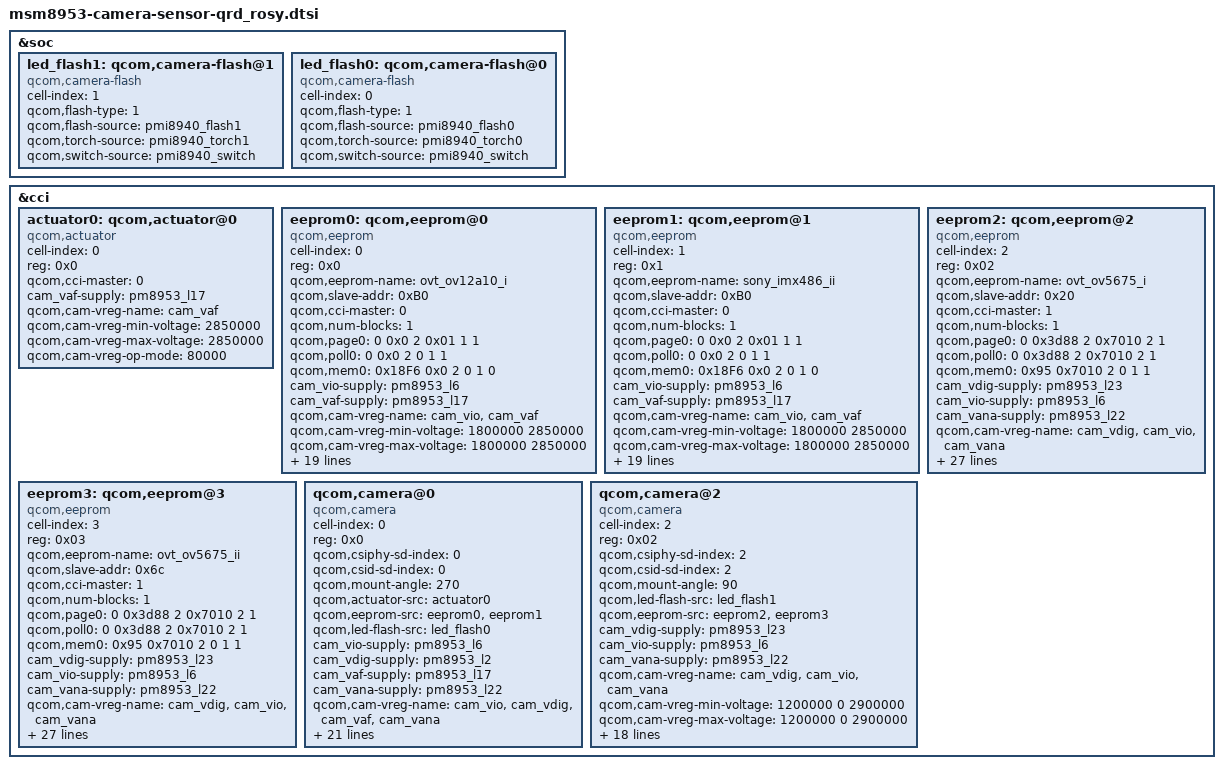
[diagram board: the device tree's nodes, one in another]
/*
 * Copyright (c) 2015-2016, The Linux Foundation. All rights reserved.
 *
 * This program is free software; you can redistribute it and/or modify
 * it under the terms of the GNU General Public License version 2 and
 * only version 2 as published by the Free Software Foundation.
 *
 * This program is distributed in the hope that it will be useful,
 * but WITHOUT ANY WARRANTY; without even the implied warranty of
 * MERCHANTABILITY or FITNESS FOR A PARTICULAR PURPOSE.  See the
 * GNU General Public License for more details.
 */

&soc {
	led_flash1: qcom,camera-flash@1 {
		cell-index = <1>;
		compatible = "qcom,camera-flash";
		qcom,flash-type = <1>;
		qcom,flash-source = <&pmi8940_flash1>;
		qcom,torch-source = <&pmi8940_torch1>;
		qcom,switch-source = <&pmi8940_switch>;
	};

	led_flash0: qcom,camera-flash@0 {
		cell-index = <0>;
		compatible = "qcom,camera-flash";
		qcom,flash-type = <1>;
		qcom,flash-source = <&pmi8940_flash0>;
		qcom,torch-source = <&pmi8940_torch0>;
		qcom,switch-source = <&pmi8940_switch>;
	};
};

&cci {
	actuator0: qcom,actuator@0 {
		cell-index = <0>;
		reg = <0x0>;
		compatible = "qcom,actuator";
		qcom,cci-master = <0>;
		cam_vaf-supply = <&pm8953_l17>;
		qcom,cam-vreg-name = "cam_vaf";
		qcom,cam-vreg-min-voltage = <2850000>;
		qcom,cam-vreg-max-voltage = <2850000>;
		qcom,cam-vreg-op-mode = <80000>;
	};

	eeprom0: qcom,eeprom@0 {
		cell-index = <0>;
		reg = <0x0>;
		qcom,eeprom-name = "ovt_ov12a10_i";
		compatible = "qcom,eeprom";
		qcom,slave-addr = <0xB0>;
		qcom,cci-master = <0>;
		qcom,num-blocks = <1>;

		qcom,page0 = <0 0x0 2 0x01 1 1>;
		qcom,poll0 = <0 0x0 2 0 1 1>;
		qcom,mem0 = <0x18F6 0x0 2 0 1 0>;

		cam_vio-supply = <&pm8953_l6>;
		cam_vaf-supply = <&pm8953_l17>;
		qcom,cam-vreg-name = "cam_vio", "cam_vaf";
		qcom,cam-vreg-min-voltage = <1800000 2850000>;
		qcom,cam-vreg-max-voltage = <1800000 2850000>;
		qcom,cam-vreg-op-mode = <100000 100000>;
		pinctrl-names = "cam_default", "cam_suspend";
		pinctrl-0 = <&cam_sensor_mclk0_default
						&cam_sensor_rear_default>;
		pinctrl-1 = <&cam_sensor_mclk0_sleep &cam_sensor_rear_sleep>;
		gpios = <&tlmm 26 0>,
			<&tlmm 40 0>;
		qcom,gpio-reset = <1>;
		qcom,gpio-req-tbl-num = <0 1>;
		qcom,gpio-req-tbl-flags = <1 0>;
		qcom,gpio-req-tbl-label = "CAMIF_MCLK0",
			"CAM_RESET0";
		qcom,cam-power-seq-type = "sensor_vreg", "sensor_vreg";
		qcom,cam-power-seq-val = "cam_vio", "cam_vaf";
		qcom,cam-power-seq-cfg-val = <1 1>;
		qcom,cam-power-seq-delay = <5 5>;
		status = "ok";
		clocks = <&clock_gcc clk_mclk0_clk_src>,
				<&clock_gcc clk_gcc_camss_mclk0_clk>;
		clock-names = "cam_src_clk", "cam_clk";
		qcom,clock-rates = <24000000 0>;
	};
	eeprom1: qcom,eeprom@1 {
		cell-index = <1>;
		reg = <0x1>;
		qcom,eeprom-name = "sony_imx486_ii";
		compatible = "qcom,eeprom";
		qcom,slave-addr = <0xB0>;
		qcom,cci-master = <0>;
		qcom,num-blocks = <1>;

		qcom,page0 = <0 0x0 2 0x01 1 1>;
		qcom,poll0 = <0 0x0 2 0 1 1>;
		qcom,mem0 = <0x18F6 0x0 2 0 1 0>;

		cam_vio-supply = <&pm8953_l6>;
		cam_vaf-supply = <&pm8953_l17>;
		qcom,cam-vreg-name = "cam_vio", "cam_vaf";
		qcom,cam-vreg-min-voltage = <1800000 2850000>;
		qcom,cam-vreg-max-voltage = <1800000 2850000>;
		qcom,cam-vreg-op-mode = <100000 100000>;
		pinctrl-names = "cam_default", "cam_suspend";
		pinctrl-0 = <&cam_sensor_mclk0_default
						&cam_sensor_rear_default>;
		pinctrl-1 = <&cam_sensor_mclk0_sleep &cam_sensor_rear_sleep>;
		gpios = <&tlmm 26 0>,
			<&tlmm 40 0>;
		qcom,gpio-reset = <1>;
		qcom,gpio-req-tbl-num = <0 1>;
		qcom,gpio-req-tbl-flags = <1 0>;
		qcom,gpio-req-tbl-label = "CAMIF_MCLK0",
			"CAM_RESET0";
		qcom,cam-power-seq-type = "sensor_vreg", "sensor_vreg";
		qcom,cam-power-seq-val = "cam_vio", "cam_vaf";
		qcom,cam-power-seq-cfg-val = <1 1>;
		qcom,cam-power-seq-delay = <5 5>;
		status = "ok";
		clocks = <&clock_gcc clk_mclk0_clk_src>,
				<&clock_gcc clk_gcc_camss_mclk0_clk>;
		clock-names = "cam_src_clk", "cam_clk";
		qcom,clock-rates = <24000000 0>;
	};

	eeprom2: qcom,eeprom@2{
		cell-index = <2>;
		reg = <0x02>;
		qcom,eeprom-name = "ovt_ov5675_i";
		compatible = "qcom,eeprom";
		qcom,slave-addr = <0x20>;
		qcom,cci-master = <1>;
		qcom,num-blocks = <1>;

		qcom,page0 = <0 0x3d88 2 0x7010 2 1>;
		qcom,poll0 = <0 0x3d88 2 0x7010 2 1>;
		qcom,mem0 = <0x95 0x7010 2 0 1 1>;

		cam_vdig-supply = <&pm8953_l23>;
		cam_vio-supply = <&pm8953_l6>;
		cam_vana-supply = <&pm8953_l22>;
		qcom,cam-vreg-name = "cam_vdig", "cam_vio", "cam_vana";
		qcom,cam-vreg-min-voltage = <1200000 1800000 2900000>;
		qcom,cam-vreg-max-voltage = <1200000 1800000 2900000>;
		qcom,cam-vreg-op-mode = <105000 80000 80000>;
		qcom,gpio-no-mux = <0>;

		pinctrl-names = "cam_default", "cam_suspend";
		pinctrl-0 = <&cam_sensor_mclk1_default
				&cam_sensor_front1_default>;
		pinctrl-1 = <&cam_sensor_mclk1_sleep
				&cam_sensor_front1_sleep>;
		gpios = <&tlmm 27 0>,
			<&tlmm 129 0>;
		qcom,gpio-reset = <1>;
		qcom,gpio-req-tbl-num = <0 1>;
		qcom,gpio-req-tbl-flags = <1 0>;
		qcom,gpio-req-tbl-label = "CAMIF_MCLK1",
					  "CAM_RESET1";

		qcom,cam-power-seq-type =
			"sensor_gpio",
			"sensor_vreg",
			"sensor_vreg",
			"sensor_vreg",
			"sensor_gpio",
			"sensor_clk";
		qcom,cam-power-seq-val =
			"sensor_gpio_reset",
			"cam_vio",
			"cam_vana",
			"cam_vdig",
			"sensor_gpio_reset",
			"sensor_cam_mclk";
		qcom,cam-power-seq-cfg-val = <0 1 1 1 1 24000000>;
		qcom,cam-power-seq-delay = <5 1 1 5 10 10>;

		status = "ok";
		clocks = <&clock_gcc clk_mclk1_clk_src>,
			<&clock_gcc clk_gcc_camss_mclk1_clk>;
		clock-names = "cam_src_clk", "cam_clk";
		qcom,clock-rates = <24000000 0>;
	};

	eeprom3: qcom,eeprom@3{
		cell-index = <3>;
		reg = <0x03>;
		qcom,eeprom-name = "ovt_ov5675_ii";
		compatible = "qcom,eeprom";
		qcom,slave-addr = <0x6c>;
		qcom,cci-master = <1>;
		qcom,num-blocks = <1>;

		qcom,page0 = <0 0x3d88 2 0x7010 2 1>;
		qcom,poll0 = <0 0x3d88 2 0x7010 2 1>;
		qcom,mem0 = <0x95 0x7010 2 0 1 1>;

		cam_vdig-supply = <&pm8953_l23>;
		cam_vio-supply = <&pm8953_l6>;
		cam_vana-supply = <&pm8953_l22>;
		qcom,cam-vreg-name = "cam_vdig", "cam_vio", "cam_vana";
		qcom,cam-vreg-min-voltage = <1200000 1800000 2900000>;
		qcom,cam-vreg-max-voltage = <1200000 1800000 2900000>;
		qcom,cam-vreg-op-mode = <105000 80000 80000>;
		qcom,gpio-no-mux = <0>;

		pinctrl-names = "cam_default", "cam_suspend";
		pinctrl-0 = <&cam_sensor_mclk1_default
				&cam_sensor_front1_default>;
		pinctrl-1 = <&cam_sensor_mclk1_sleep
				&cam_sensor_front1_sleep>;
		gpios = <&tlmm 27 0>,
			<&tlmm 129 0>;
		qcom,gpio-reset = <1>;
		qcom,gpio-req-tbl-num = <0 1>;
		qcom,gpio-req-tbl-flags = <1 0>;
		qcom,gpio-req-tbl-label = "CAMIF_MCLK1",
					  "CAM_RESET1";

		qcom,cam-power-seq-type =
			"sensor_gpio",
			"sensor_vreg",
			"sensor_vreg",
			"sensor_vreg",
			"sensor_gpio",
			"sensor_clk";
		qcom,cam-power-seq-val =
			"sensor_gpio_reset",
			"cam_vio",
			"cam_vana",
			"cam_vdig",
			"sensor_gpio_reset",
			"sensor_cam_mclk";
		qcom,cam-power-seq-cfg-val = <0 1 1 1 1 24000000>;
		qcom,cam-power-seq-delay = <5 1 1 5 10 10>;

		status = "ok";
		clocks = <&clock_gcc clk_mclk1_clk_src>,
			<&clock_gcc clk_gcc_camss_mclk1_clk>;
		clock-names = "cam_src_clk", "cam_clk";
		qcom,clock-rates = <24000000 0>;
	};

	qcom,camera@0 {
		cell-index = <0>;
		compatible = "qcom,camera";
		reg = <0x0>;
		qcom,csiphy-sd-index = <0>;
		qcom,csid-sd-index = <0>;
		qcom,mount-angle = <270>;
		qcom,actuator-src = <&actuator0>;
		qcom,eeprom-src = <&eeprom0 &eeprom1>;
		qcom,led-flash-src = <&led_flash0>;
		cam_vio-supply = <&pm8953_l6>;
		cam_vdig-supply = <&pm8953_l2>;
		cam_vaf-supply = <&pm8953_l17>;
		cam_vana-supply = <&pm8953_l22>;
		qcom,cam-vreg-name = "cam_vio", "cam_vdig", "cam_vaf",
						"cam_vana";
		qcom,cam-vreg-min-voltage = <0 1200000 2850000 2900000>;
		qcom,cam-vreg-max-voltage = <0 1200000 2850000 2900000>;
		qcom,cam-vreg-op-mode = <0 105000 100000 80000>;
		pinctrl-names = "cam_default", "cam_suspend";
		pinctrl-0 = <&cam_sensor_mclk0_default
				&cam_sensor_rear_default>;
		pinctrl-1 = <&cam_sensor_mclk0_sleep &cam_sensor_rear_sleep>;
		gpios = <&tlmm 26 0>,
			<&tlmm 40 0>;
		qcom,gpio-reset = <1>;
		qcom,gpio-req-tbl-num = <0 1>;
		qcom,gpio-req-tbl-flags = <1 0>;
		qcom,gpio-req-tbl-label = "CAMIF_MCLK0",
			"CAM_RESET0";
		qcom,sensor-position = <0>;
		qcom,sensor-mode = <0>;
		qcom,cci-master = <0>;
		status = "ok";
		clocks = <&clock_gcc clk_mclk0_clk_src>,
				<&clock_gcc clk_gcc_camss_mclk0_clk>;
		clock-names = "cam_src_clk", "cam_clk";
		qcom,clock-rates = <24000000 0>;
	};
	qcom,camera@2 {
		cell-index = <2>;
		compatible = "qcom,camera";
		reg = <0x02>;
		qcom,csiphy-sd-index = <2>;
		qcom,csid-sd-index = <2>;
		qcom,mount-angle = <90>;
		qcom,led-flash-src = <&led_flash1>;
		qcom,eeprom-src = <&eeprom2 &eeprom3>;
		cam_vdig-supply = <&pm8953_l23>;
		cam_vio-supply = <&pm8953_l6>;
		cam_vana-supply = <&pm8953_l22>;
		qcom,cam-vreg-name = "cam_vdig", "cam_vio", "cam_vana";
		qcom,cam-vreg-min-voltage = <1200000 0 2900000>;
		qcom,cam-vreg-max-voltage = <1200000 0 2900000>;
		qcom,cam-vreg-op-mode = <105000 0 80000>;
		qcom,gpio-no-mux = <0>;
		pinctrl-names = "cam_default", "cam_suspend";
		pinctrl-0 = <&cam_sensor_mclk1_default
				&cam_sensor_front1_default>;
		pinctrl-1 = <&cam_sensor_mclk1_sleep
				&cam_sensor_front1_sleep>;
		gpios = <&tlmm 27 0>,
			<&tlmm 129 0>;
		qcom,gpio-reset = <1>;
		qcom,gpio-req-tbl-num = <0 1>;
		qcom,gpio-req-tbl-flags = <1 0>;
		qcom,gpio-req-tbl-label = "CAMIF_MCLK1",
					  "CAM_RESET1";
		qcom,sensor-position = <1>;
		qcom,sensor-mode = <0>;
		qcom,cci-master = <1>;
		status = "ok";
		clocks = <&clock_gcc clk_mclk1_clk_src>,
			<&clock_gcc clk_gcc_camss_mclk1_clk>;
		clock-names = "cam_src_clk", "cam_clk";
		qcom,clock-rates = <24000000 0>;
	};
};
